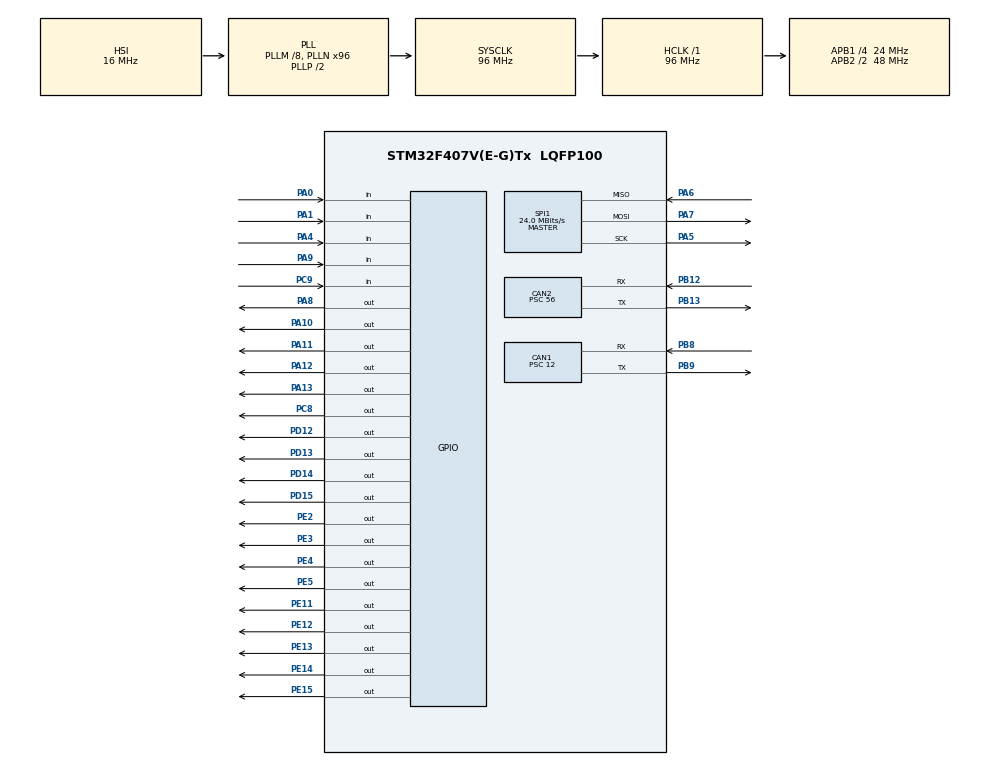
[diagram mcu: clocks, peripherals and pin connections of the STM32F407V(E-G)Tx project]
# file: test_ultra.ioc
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CAN1.BS1=CAN_BS1_13TQ
CAN1.BS2=CAN_BS2_2TQ
CAN1.CalculateBaudRate=125000
CAN1.CalculateTimeBit=8000
CAN1.CalculateTimeQuantum=500.0
CAN1.Prescaler=12
CAN2.CalculateBaudRate=142857
CAN2.CalculateTimeBit=7000
CAN2.CalculateTimeQuantum=2333.333333333333
CAN2.Prescaler=56
FREERTOS.Tasks01=defaultTask,0,128,StartDefaultTask,Default,NULL,Dynamic,NULL,NULL
Mcu.Family=STM32F4
Mcu.Name=STM32F407V(E-G)Tx
Mcu.Package=LQFP100
NVIC.PriorityGroup=NVIC_PRIORITYGROUP_4
PA0-WKUP.Signal=GPIO_Input
PA1.Signal=GPIO_Input
PA10.Signal=GPIO_Output
PA11.Signal=GPIO_Output
PA12.Signal=GPIO_Output
PA13.Signal=GPIO_Output
PA4.Signal=GPIO_Input
PA5.Mode=Full_Duplex_Master
PA5.Signal=SPI1_SCK
PA6.Mode=Full_Duplex_Master
PA6.Signal=SPI1_MISO
PA7.Mode=Full_Duplex_Master
PA7.Signal=SPI1_MOSI
PA8.Signal=GPIO_Output
PA9.Signal=GPIO_Input
PB12.Mode=CAN_Activate
PB12.Signal=CAN2_RX
PB13.Mode=CAN_Activate
PB13.Signal=CAN2_TX
PB8.Mode=CAN_Activate
PB8.Signal=CAN1_RX
PB9.Mode=CAN_Activate
PB9.Signal=CAN1_TX
PC8.Signal=GPIO_Output
PC9.Signal=GPIO_Input
PD12.Signal=GPIO_Output
PD13.Signal=GPIO_Output
PD14.Signal=GPIO_Output
PD15.Signal=GPIO_Output
PE11.Signal=GPIO_Output
PE12.Signal=GPIO_Output
PE13.Signal=GPIO_Output
PE14.Signal=GPIO_Output
PE15.Signal=GPIO_Output
PE2.Signal=GPIO_Output
PE3.Signal=GPIO_Output
PE4.Signal=GPIO_Output
PE5.Signal=GPIO_Output
PH0-OSC_IN.Mode=HSE-External-Oscillator
PH0-OSC_IN.Signal=RCC_OSC_IN
PH1-OSC_OUT.Mode=HSE-External-Oscillator
PH1-OSC_OUT.Signal=RCC_OSC_OUT
ProjectManager.HeapSize=0x200
ProjectManager.StackSize=0x400
ProjectManager.TargetToolchain=STM32CubeIDE
RCC.48MHZClocksFreq_Value=48000000
RCC.AHBFreq_Value=96000000
RCC.APB1CLKDivider=RCC_HCLK_DIV4
RCC.APB1Freq_Value=24000000
RCC.APB1TimFreq_Value=48000000
RCC.APB2CLKDivider=RCC_HCLK_DIV2
RCC.APB2Freq_Value=48000000
RCC.APB2TimFreq_Value=96000000
RCC.CortexFreq_Value=96000000
RCC.HCLKFreq_Value=96000000
RCC.HSE_VALUE=8000000
RCC.HSI_VALUE=16000000
RCC.LSE_VALUE=32768
RCC.PLLM=8
RCC.PLLN=96
RCC.SYSCLKFreq_VALUE=96000000
RCC.SYSCLKSource=RCC_SYSCLKSOURCE_PLLCLK
RCC.VCOOutputFreq_Value=192000000
SPI1.CalculateBaudRate=24.0 MBits/s
SPI1.Direction=SPI_DIRECTION_2LINES
SPI1.Mode=SPI_MODE_MASTER
SPI1.VirtualType=VM_MASTER
TIM1.Period=0xffff-1
TIM1.Prescaler=83
TIM2.Prescaler=16
TIM4.Prescaler=16-1
VP_FREERTOS_VS_CMSIS_V1.Mode=CMSIS_V1
VP_TIM1_VS_ClockSourceINT.Mode=Internal
VP_TIM2_VS_ClockSourceINT.Mode=Internal
VP_TIM4_VS_ClockSourceINT.Mode=Internal
VP_TIM6_VS_ClockSourceINT.Mode=Enable_Timer
VP_TIM7_VS_ClockSourceINT.Mode=Enable_Timer
board=custom

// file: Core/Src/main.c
/* USER CODE BEGIN Header */
/**
  ******************************************************************************
  * @file           : main.c
  * @brief          : Main program body
  ******************************************************************************
  * @attention
  *
  * Copyright (c) 2022 STMicroelectronics.
  * All rights reserved.
  *
  * This software is licensed under terms that can be found in the LICENSE file
  * in the root directory of this software component.
  * If no LICENSE file comes with this software, it is provided AS-IS.
  *
  ******************************************************************************
  */
/* USER CODE END Header */
#include "main.h"
#include "cmsis_os.h"

CAN_HandleTypeDef hcan1;
CAN_HandleTypeDef hcan2;

SPI_HandleTypeDef hspi1;

TIM_HandleTypeDef htim1;
TIM_HandleTypeDef htim2;
TIM_HandleTypeDef htim4;
TIM_HandleTypeDef htim6;
TIM_HandleTypeDef htim7;

osThreadId defaultTaskHandle;
/* USER CODE BEGIN PV */

uint32_t echo1, echo2, dist1, dist2;
/* USER CODE END PV */

void SystemClock_Config(void);
static void MX_GPIO_Init(void);
static void MX_TIM4_Init(void);
static void MX_TIM1_Init(void);
static void MX_CAN1_Init(void);
static void MX_CAN2_Init(void);
static void MX_SPI1_Init(void);
static void MX_TIM2_Init(void);
static void MX_TIM6_Init(void);
static void MX_TIM7_Init(void);
void StartDefaultTask(void const * argument);

/* USER CODE BEGIN PFP */
void vTask1( void *pvParameters );
void vTask2( void *pvParameters );
void vTask3( void *pvParameters );
/* USER CODE END PFP */

int main(void)
{
  /* USER CODE BEGIN 1 */
	BaseType_t ret = 0;
  /* USER CODE END 1 */

  /* MCU Configuration--------------------------------------------------------*/

  /* Reset of all peripherals, Initializes the Flash interface and the Systick. */
  HAL_Init();

  /* Configure the system clock */
  SystemClock_Config();

  /* Initialize all configured peripherals */
  MX_GPIO_Init();
  MX_TIM4_Init();
  MX_TIM1_Init();
  MX_CAN1_Init();
  MX_CAN2_Init();
  MX_SPI1_Init();
  MX_TIM2_Init();
  MX_TIM6_Init();
  MX_TIM7_Init();

  /* Create the thread(s) */
  /* definition and creation of defaultTask */
  osThreadDef(defaultTask, StartDefaultTask, osPriorityNormal, 0, 128);
  defaultTaskHandle = osThreadCreate(osThread(defaultTask), NULL);

  /* Start scheduler */
  osKernelStart();

  /* We should never get here as control is now taken by the scheduler */
  /* Infinite loop */
  while (1)
  {

  }
}

void SystemClock_Config(void)
{
  RCC_OscInitTypeDef RCC_OscInitStruct = {0};
  RCC_ClkInitTypeDef RCC_ClkInitStruct = {0};

  /** Configure the main internal regulator output voltage
  */
  __HAL_RCC_PWR_CLK_ENABLE();
  __HAL_PWR_VOLTAGESCALING_CONFIG(PWR_REGULATOR_VOLTAGE_SCALE1);

  /** Initializes the RCC Oscillators according to the specified parameters
  * in the RCC_OscInitTypeDef structure.
  */
  RCC_OscInitStruct.OscillatorType = RCC_OSCILLATORTYPE_HSI;
  RCC_OscInitStruct.HSIState = RCC_HSI_ON;
  RCC_OscInitStruct.HSICalibrationValue = RCC_HSICALIBRATION_DEFAULT;
  RCC_OscInitStruct.PLL.PLLState = RCC_PLL_ON;
  RCC_OscInitStruct.PLL.PLLSource = RCC_PLLSOURCE_HSI;
  RCC_OscInitStruct.PLL.PLLM = 8;
  RCC_OscInitStruct.PLL.PLLN = 96;
  RCC_OscInitStruct.PLL.PLLP = RCC_PLLP_DIV2;
  RCC_OscInitStruct.PLL.PLLQ = 4;
  if (HAL_RCC_OscConfig(&RCC_OscInitStruct) != HAL_OK)
  {
    Error_Handler();
  }

  /** Initializes the CPU, AHB and APB buses clocks
  */
  RCC_ClkInitStruct.ClockType = RCC_CLOCKTYPE_HCLK|RCC_CLOCKTYPE_SYSCLK
                              |RCC_CLOCKTYPE_PCLK1|RCC_CLOCKTYPE_PCLK2;
  RCC_ClkInitStruct.SYSCLKSource = RCC_SYSCLKSOURCE_PLLCLK;
  RCC_ClkInitStruct.AHBCLKDivider = RCC_SYSCLK_DIV1;
  RCC_ClkInitStruct.APB1CLKDivider = RCC_HCLK_DIV4;
  RCC_ClkInitStruct.APB2CLKDivider = RCC_HCLK_DIV2;

  if (HAL_RCC_ClockConfig(&RCC_ClkInitStruct, FLASH_LATENCY_3) != HAL_OK)
  {
    Error_Handler();
  }
}

static void MX_CAN1_Init(void)
{

  hcan1.Instance = CAN1;
  hcan1.Init.Prescaler = 12;
  hcan1.Init.Mode = CAN_MODE_NORMAL;
  hcan1.Init.SyncJumpWidth = CAN_SJW_1TQ;
  hcan1.Init.TimeSeg1 = CAN_BS1_13TQ;
  hcan1.Init.TimeSeg2 = CAN_BS2_2TQ;
  hcan1.Init.TimeTriggeredMode = DISABLE;
  hcan1.Init.AutoBusOff = DISABLE;
  hcan1.Init.AutoWakeUp = DISABLE;
  hcan1.Init.AutoRetransmission = DISABLE;
  hcan1.Init.ReceiveFifoLocked = DISABLE;
  hcan1.Init.TransmitFifoPriority = DISABLE;
  if (HAL_CAN_Init(&hcan1) != HAL_OK)
  {
    Error_Handler();
  }

}

static void MX_CAN2_Init(void)
{

  hcan2.Instance = CAN2;
  hcan2.Init.Prescaler = 56;
  hcan2.Init.Mode = CAN_MODE_NORMAL;
  hcan2.Init.SyncJumpWidth = CAN_SJW_1TQ;
  hcan2.Init.TimeSeg1 = CAN_BS1_1TQ;
  hcan2.Init.TimeSeg2 = CAN_BS2_1TQ;
  hcan2.Init.TimeTriggeredMode = DISABLE;
  hcan2.Init.AutoBusOff = DISABLE;
  hcan2.Init.AutoWakeUp = DISABLE;
  hcan2.Init.AutoRetransmission = DISABLE;
  hcan2.Init.ReceiveFifoLocked = DISABLE;
  hcan2.Init.TransmitFifoPriority = DISABLE;
  if (HAL_CAN_Init(&hcan2) != HAL_OK)
  {
    Error_Handler();
  }

}

static void MX_SPI1_Init(void)
{

  /* SPI1 parameter configuration*/
  hspi1.Instance = SPI1;
  hspi1.Init.Mode = SPI_MODE_MASTER;
  hspi1.Init.Direction = SPI_DIRECTION_2LINES;
  hspi1.Init.DataSize = SPI_DATASIZE_8BIT;
  hspi1.Init.CLKPolarity = SPI_POLARITY_LOW;
  hspi1.Init.CLKPhase = SPI_PHASE_1EDGE;
  hspi1.Init.NSS = SPI_NSS_SOFT;
  hspi1.Init.BaudRatePrescaler = SPI_BAUDRATEPRESCALER_2;
  hspi1.Init.FirstBit = SPI_FIRSTBIT_MSB;
  hspi1.Init.TIMode = SPI_TIMODE_DISABLE;
  hspi1.Init.CRCCalculation = SPI_CRCCALCULATION_DISABLE;
  hspi1.Init.CRCPolynomial = 10;
  if (HAL_SPI_Init(&hspi1) != HAL_OK)
  {
    Error_Handler();
  }

}

static void MX_TIM1_Init(void)
{

  TIM_ClockConfigTypeDef sClockSourceConfig = {0};
  TIM_MasterConfigTypeDef sMasterConfig = {0};

  htim1.Instance = TIM1;
  htim1.Init.Prescaler = 83;
  htim1.Init.CounterMode = TIM_COUNTERMODE_UP;
  htim1.Init.Period = 0xffff-1;
  htim1.Init.ClockDivision = TIM_CLOCKDIVISION_DIV1;
  htim1.Init.RepetitionCounter = 0;
  htim1.Init.AutoReloadPreload = TIM_AUTORELOAD_PRELOAD_DISABLE;
  if (HAL_TIM_Base_Init(&htim1) != HAL_OK)
  {
    Error_Handler();
  }
  sClockSourceConfig.ClockSource = TIM_CLOCKSOURCE_INTERNAL;
  if (HAL_TIM_ConfigClockSource(&htim1, &sClockSourceConfig) != HAL_OK)
  {
    Error_Handler();
  }
  sMasterConfig.MasterOutputTrigger = TIM_TRGO_RESET;
  sMasterConfig.MasterSlaveMode = TIM_MASTERSLAVEMODE_DISABLE;
  if (HAL_TIMEx_MasterConfigSynchronization(&htim1, &sMasterConfig) != HAL_OK)
  {
    Error_Handler();
  }

}

static void MX_TIM2_Init(void)
{

  TIM_ClockConfigTypeDef sClockSourceConfig = {0};
  TIM_MasterConfigTypeDef sMasterConfig = {0};

  htim2.Instance = TIM2;
  htim2.Init.Prescaler = 16;
  htim2.Init.CounterMode = TIM_COUNTERMODE_UP;
  htim2.Init.Period = 4294967295;
  htim2.Init.ClockDivision = TIM_CLOCKDIVISION_DIV1;
  htim2.Init.AutoReloadPreload = TIM_AUTORELOAD_PRELOAD_DISABLE;
  if (HAL_TIM_Base_Init(&htim2) != HAL_OK)
  {
    Error_Handler();
  }
  sClockSourceConfig.ClockSource = TIM_CLOCKSOURCE_INTERNAL;
  if (HAL_TIM_ConfigClockSource(&htim2, &sClockSourceConfig) != HAL_OK)
  {
    Error_Handler();
  }
  sMasterConfig.MasterOutputTrigger = TIM_TRGO_RESET;
  sMasterConfig.MasterSlaveMode = TIM_MASTERSLAVEMODE_DISABLE;
  if (HAL_TIMEx_MasterConfigSynchronization(&htim2, &sMasterConfig) != HAL_OK)
  {
    Error_Handler();
  }

}

static void MX_TIM4_Init(void)
{

  TIM_ClockConfigTypeDef sClockSourceConfig = {0};
  TIM_MasterConfigTypeDef sMasterConfig = {0};

  htim4.Instance = TIM4;
  htim4.Init.Prescaler = 16-1;
  htim4.Init.CounterMode = TIM_COUNTERMODE_UP;
  htim4.Init.Period = 65535;
  htim4.Init.ClockDivision = TIM_CLOCKDIVISION_DIV1;
  htim4.Init.AutoReloadPreload = TIM_AUTORELOAD_PRELOAD_DISABLE;
  if (HAL_TIM_Base_Init(&htim4) != HAL_OK)
  {
    Error_Handler();
  }
  sClockSourceConfig.ClockSource = TIM_CLOCKSOURCE_INTERNAL;
  if (HAL_TIM_ConfigClockSource(&htim4, &sClockSourceConfig) != HAL_OK)
  {
    Error_Handler();
  }
  sMasterConfig.MasterOutputTrigger = TIM_TRGO_RESET;
  sMasterConfig.MasterSlaveMode = TIM_MASTERSLAVEMODE_DISABLE;
  if (HAL_TIMEx_MasterConfigSynchronization(&htim4, &sMasterConfig) != HAL_OK)
  {
    Error_Handler();
  }

}

static void MX_TIM6_Init(void)
{

  TIM_MasterConfigTypeDef sMasterConfig = {0};

  htim6.Instance = TIM6;
  htim6.Init.Prescaler = 0;
  htim6.Init.CounterMode = TIM_COUNTERMODE_UP;
  htim6.Init.Period = 65535;
  htim6.Init.AutoReloadPreload = TIM_AUTORELOAD_PRELOAD_DISABLE;
  if (HAL_TIM_Base_Init(&htim6) != HAL_OK)
  {
    Error_Handler();
  }
  sMasterConfig.MasterOutputTrigger = TIM_TRGO_RESET;
  sMasterConfig.MasterSlaveMode = TIM_MASTERSLAVEMODE_DISABLE;
  if (HAL_TIMEx_MasterConfigSynchronization(&htim6, &sMasterConfig) != HAL_OK)
  {
    Error_Handler();
  }

}

static void MX_TIM7_Init(void)
{

  TIM_MasterConfigTypeDef sMasterConfig = {0};

  htim7.Instance = TIM7;
  htim7.Init.Prescaler = 0;
  htim7.Init.CounterMode = TIM_COUNTERMODE_UP;
  htim7.Init.Period = 65535;
  htim7.Init.AutoReloadPreload = TIM_AUTORELOAD_PRELOAD_DISABLE;
  if (HAL_TIM_Base_Init(&htim7) != HAL_OK)
  {
    Error_Handler();
  }
  sMasterConfig.MasterOutputTrigger = TIM_TRGO_RESET;
  sMasterConfig.MasterSlaveMode = TIM_MASTERSLAVEMODE_DISABLE;
  if (HAL_TIMEx_MasterConfigSynchronization(&htim7, &sMasterConfig) != HAL_OK)
  {
    Error_Handler();
  }

}

static void MX_GPIO_Init(void)
{
  GPIO_InitTypeDef GPIO_InitStruct = {0};

  /* GPIO Ports Clock Enable */
  __HAL_RCC_GPIOE_CLK_ENABLE();
  __HAL_RCC_GPIOH_CLK_ENABLE();
  __HAL_RCC_GPIOA_CLK_ENABLE();
  __HAL_RCC_GPIOB_CLK_ENABLE();
  __HAL_RCC_GPIOD_CLK_ENABLE();
  __HAL_RCC_GPIOC_CLK_ENABLE();

  /*Configure GPIO pin Output Level */
  HAL_GPIO_WritePin(GPIOE, GPIO_PIN_2|GPIO_PIN_3|GPIO_PIN_4|GPIO_PIN_5
                          |GPIO_PIN_11|GPIO_PIN_12|GPIO_PIN_13|GPIO_PIN_14
                          |GPIO_PIN_15, GPIO_PIN_RESET);

  /*Configure GPIO pin Output Level */
  HAL_GPIO_WritePin(GPIOD, GPIO_PIN_12|GPIO_PIN_13|GPIO_PIN_14|GPIO_PIN_15, GPIO_PIN_RESET);

  /*Configure GPIO pin Output Level */
  HAL_GPIO_WritePin(GPIOC, GPIO_PIN_8, GPIO_PIN_RESET);

  /*Configure GPIO pin Output Level */
  HAL_GPIO_WritePin(GPIOA, GPIO_PIN_8|GPIO_PIN_10|GPIO_PIN_11|GPIO_PIN_12
                          |GPIO_PIN_13, GPIO_PIN_RESET);

  /*Configure GPIO pins : PE2 PE3 PE4 PE5
                           PE11 PE12 PE13 PE14
                           PE15 */
  GPIO_InitStruct.Pin = GPIO_PIN_2|GPIO_PIN_3|GPIO_PIN_4|GPIO_PIN_5
                          |GPIO_PIN_11|GPIO_PIN_12|GPIO_PIN_13|GPIO_PIN_14
                          |GPIO_PIN_15;
  GPIO_InitStruct.Mode = GPIO_MODE_OUTPUT_PP;
  GPIO_InitStruct.Pull = GPIO_NOPULL;
  GPIO_InitStruct.Speed = GPIO_SPEED_FREQ_LOW;
  HAL_GPIO_Init(GPIOE, &GPIO_InitStruct);

  /*Configure GPIO pins : PA0 PA1 PA4 PA9 */
  GPIO_InitStruct.Pin = GPIO_PIN_0|GPIO_PIN_1|GPIO_PIN_4|GPIO_PIN_9;
  GPIO_InitStruct.Mode = GPIO_MODE_INPUT;
  GPIO_InitStruct.Pull = GPIO_NOPULL;
  HAL_GPIO_Init(GPIOA, &GPIO_InitStruct);

  /*Configure GPIO pins : PD12 PD13 PD14 PD15 */
  GPIO_InitStruct.Pin = GPIO_PIN_12|GPIO_PIN_13|GPIO_PIN_14|GPIO_PIN_15;
  GPIO_InitStruct.Mode = GPIO_MODE_OUTPUT_PP;
  GPIO_InitStruct.Pull = GPIO_NOPULL;
  GPIO_InitStruct.Speed = GPIO_SPEED_FREQ_LOW;
  HAL_GPIO_Init(GPIOD, &GPIO_InitStruct);

  /*Configure GPIO pin : PC8 */
  GPIO_InitStruct.Pin = GPIO_PIN_8;
  GPIO_InitStruct.Mode = GPIO_MODE_OUTPUT_PP;
  GPIO_InitStruct.Pull = GPIO_NOPULL;
  GPIO_InitStruct.Speed = GPIO_SPEED_FREQ_LOW;
  HAL_GPIO_Init(GPIOC, &GPIO_InitStruct);

  /*Configure GPIO pin : PC9 */
  GPIO_InitStruct.Pin = GPIO_PIN_9;
  GPIO_InitStruct.Mode = GPIO_MODE_INPUT;
  GPIO_InitStruct.Pull = GPIO_NOPULL;
  HAL_GPIO_Init(GPIOC, &GPIO_InitStruct);

  /*Configure GPIO pins : PA8 PA10 PA11 PA12
                           PA13 */
  GPIO_InitStruct.Pin = GPIO_PIN_8|GPIO_PIN_10|GPIO_PIN_11|GPIO_PIN_12
                          |GPIO_PIN_13;
  GPIO_InitStruct.Mode = GPIO_MODE_OUTPUT_PP;
  GPIO_InitStruct.Pull = GPIO_NOPULL;
  GPIO_InitStruct.Speed = GPIO_SPEED_FREQ_LOW;
  HAL_GPIO_Init(GPIOA, &GPIO_InitStruct);

}

void StartDefaultTask(void const * argument)
{
  for(;;)
  {
    osDelay(1);
  }
}

void Error_Handler(void)
{
  __disable_irq();
  while (1)
  {
  }
}
